AUTOSAR XML (schema 00048)
package /ComponentTypes
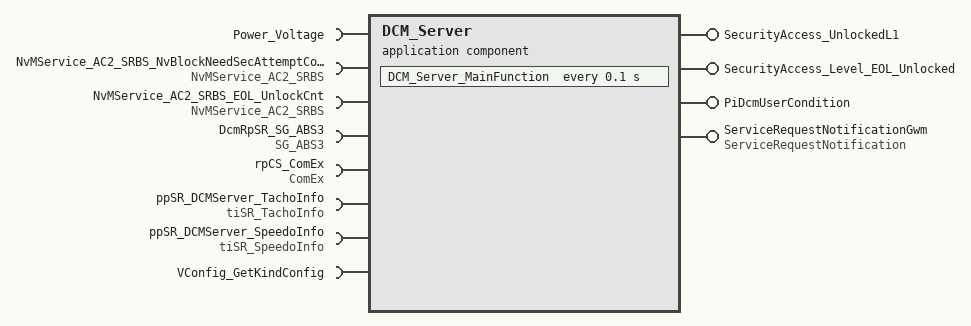
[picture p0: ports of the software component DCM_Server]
  application sw component type DCM_Server
    provide port SecurityAccess_UnlockedL1: provided-interface=SecurityAccess_UnlockedL1
      provided-com-specs:
        operation=CompareKey, queue-length=1
        operation=GetSeed, queue-length=1
        operation=SetSecurityAttemptCounter, queue-length=1
        operation=GetSecurityAttemptCounter, queue-length=1
    provide port SecurityAccess_Level_EOL_Unlocked: provided-interface=SecurityAccess_Level_EOL_Unlocked
      provided-com-specs:
        operation=CompareKey, queue-length=1
        operation=GetSeed, queue-length=1
        operation=SetSecurityAttemptCounter, queue-length=1
        operation=GetSecurityAttemptCounter, queue-length=1
    require port Power_Voltage: nonqueued-receiver-com-spec{data-element=Element, filter=data-filter-type=ALWAYS, init-value=fields=[state:0, value:0]}, required-interface=Power_Voltage
    require port NvMService_AC2_SRBS_NvBlockNeedSecAttemptCount: required-com-specs=[WriteBlock, SetRamBlockStatus, ReadBlock, GetErrorStatus], required-interface=NvMService_AC2_SRBS
    require port NvMService_AC2_SRBS_EOL_UnlockCnt: required-com-specs=[WriteBlock, SetRamBlockStatus, ReadBlock, GetErrorStatus], required-interface=NvMService_AC2_SRBS
    provide port PiDcmUserCondition: mode-switch-sender-com-spec{mode-group=Mode, queue-length=1}, provided-interface=PiDcmUserCondition
    require port DcmRpSR_SG_ABS3: nonqueued-receiver-com-spec{data-element=SG_ABS3, alive-timeout=0.2, enable-update=true, handle-never-received=true, init-value=fields=[ABSActv_0x265:0, ABSFailSts_0x265:1, CheckSum_ABS3_0x265:0, dummy_ABS3_0:0, dummy_ABS3_1:0, dummy_ABS3_2:0, dummy_ABS3_3:0, EBDActv_0x265:0, EBDFailSts_0x265:0, RollingCounter_ABS3_0x265:0, VehOdoInfo_0x265:0, VehOdoInfoSts_0x265:1, VehSpd_0x265:0, VehSpdVld_0x265:0]}, required-interface=SG_ABS3
    provide port ServiceRequestNotificationGwm: provided-com-specs=[{operation=Confirmation, queue-length=1}, {operation=Indication, queue-length=1}], provided-interface=ServiceRequestNotification
    4 x require port:
      rpCS_ComEx: required-com-specs=[SendSignal, ReceiveSignal, GetRxE2EStatus], required-interface=ComEx
      ppSR_DCMServer_TachoInfo: nonqueued-receiver-com-spec{data-element=Element, filter=data-filter-type=ALWAYS, init-value=fields=[EngRunSts:0, EngSpd:0, TimeOutFlag:0, EngSpdBak:0, Msg_missingSts:0]}, required-interface=tiSR_TachoInfo
      ppSR_DCMServer_SpeedoInfo: nonqueued-receiver-com-spec{data-element=Element, filter=data-filter-type=ALWAYS, init-value=fields=[OverSpdWrnFlg:0, VehRunSts:0, IndicateSpeed:0, RealSpeed:0, IndicateSpeedMile:0, RealSpeedMile:0, RealSpeedBak:0, Msg_missingSts:0, VehSpdVld:0]}, required-interface=tiSR_SpeedoInfo
      VConfig_GetKindConfig: client-com-spec=Operation_VConfig_GetKindConfig, required-interface=VConfig_GetKindConfig
    behavior DCM_Server_InternalBehavior: port-api-option{enable-take-address=true, error-handling=NO-TRANSFORMER-ERROR-HANDLING, indirect-api=false, port=ServiceRequestNotificationGwm}
      ar-typed-per-instance-memorys:
        5 x data, all with sw-calibration-access=READ-ONLY:
          NvBlockNeedSecAttmptCount_MirrorBlock: type=A_1Bytes
          NvBlockNeed_Dcm_ECUlevelNetworkConfigurationDataIdentifier_MirrorBlock: type=A_200Bytes
          NvBlockNeed_Dcm_VIN_MirrorBlock: type=A_17Bytes
          NvBlockNeedSecAttemptCount_MirrorBlock: type=A_1Bytes
          NvBlockNeed_EOLUnlockCnt_MirrorBlock: type=A_1Bytes
      timing event TMT_Runnable: start-on-event=DCM_Server_MainFunction, period=0.1
      4 x operation invoked event:
        OIT_SecurityAccess_Level_EOL_Unlocked_CompareKey_SecurityAccess_Level_EOL_Unlocked_CompareKey: start-on-event=SecurityAccess_Level_EOL_Unlocked_CompareKey, operation=SecurityAccess_Level_EOL_Unlocked.CompareKey
        OIT_SecurityAccess_Level_EOL_Unlocked_GetSeed_SecurityAccess_Level_EOL_Unlocked_GetSeed: start-on-event=SecurityAccess_Level_EOL_Unlocked_GetSeed, operation=SecurityAccess_Level_EOL_Unlocked.GetSeed
        OIT_SecurityAccess_UnlockedL1_CompareKey_SecurityAccess_UnlockedL1_CompareKey: start-on-event=SecurityAccess_UnlockedL1_CompareKey, operation=SecurityAccess_UnlockedL1.CompareKey
        OIT_SecurityAccess_UnlockedL1_GetSeed_SecurityAccess_UnlockedL1_GetSeed: start-on-event=SecurityAccess_UnlockedL1_GetSeed, operation=SecurityAccess_UnlockedL1.GetSeed
      init event DCM_Server_InitEvent: start-on-event=DCM_Server_Init
      6 x operation invoked event:
        OIT_SecurityAccess_UnlockedL1_SetSecurityAttemptCounter_SecurityAccess_UnlockedL1_SetSecurityAttemptCounter: start-on-event=SecurityAccess_UnlockedL1_SetSecurityAttemptCounter, operation=SecurityAccess_UnlockedL1.SetSecurityAttemptCounter
        OIT_SecurityAccess_UnlockedL1_GetSecurityAttemptCounter_SecurityAccess_UnlockedL1_GetSecurityAttemptCounter: start-on-event=SecurityAccess_UnlockedL1_GetSecurityAttemptCounter, operation=SecurityAccess_UnlockedL1.GetSecurityAttemptCounter
        OIT_SecurityAccess_Level_EOL_Unlocked_SetSecurityAttemptCounter_SecurityAccess_Level_EOL_Unlocked_SetSecurityAttemptCounter: start-on-event=SecurityAccess_Level_EOL_Unlocked_SetSecurityAttemptCounter, operation=SecurityAccess_Level_EOL_Unlocked.SetSecurityAttemptCounter
        OIT_SecurityAccess_Level_EOL_Unlocked_GetSecurityAttemptCounter_SecurityAccess_Level_EOL_Unlocked_GetSecurityAttemptCounter: start-on-event=SecurityAccess_Level_EOL_Unlocked_GetSecurityAttemptCounter, operation=SecurityAccess_Level_EOL_Unlocked.GetSecurityAttemptCounter
        OIT_ServiceRequestNotificationGwm_Confirmation_ServiceRequestNotificationGwm_Confirmation: start-on-event=ServiceRequestNotificationGwm_Confirmation, operation=ServiceRequestNotificationGwm.Confirmation
        OIT_ServiceRequestNotificationGwm_Indication_ServiceRequestNotificationGwm_Indication: start-on-event=ServiceRequestNotificationGwm_Indication, operation=ServiceRequestNotificationGwm.Indication
      12 x runnable:
        DCM_Server_MainFunction
          data-receive-point-by-arguments:
            access REC_DcmRpSR_SG_ABS3_SG_ABS3: accessed-variable=DcmRpSR_SG_ABS3.SG_ABS3
            access REC_ppSR_DCMServer_SpeedoInfo_Element: accessed-variable=ppSR_DCMServer_SpeedoInfo.Element
            access REC_ppSR_DCMServer_TachoInfo_Element: accessed-variable=ppSR_DCMServer_TachoInfo.Element
          mode switch point SWITCH_PiDcmUserCondition_Mode: mode-group=PiDcmUserCondition.Mode
          10 x sync call:
            SC_NvMService_AC2_SRBS_NvBlockNeedSecAttemptCount_ReadBlock: operation=NvMService_AC2_SRBS_NvBlockNeedSecAttemptCount.ReadBlock
            SC_NvMService_AC2_SRBS_NvBlockNeedSecAttemptCount_WriteBlock: operation=NvMService_AC2_SRBS_NvBlockNeedSecAttemptCount.WriteBlock
            SC_NvMService_AC2_SRBS_EOL_UnlockCnt_ReadBlock: operation=NvMService_AC2_SRBS_EOL_UnlockCnt.ReadBlock
            SC_NvMService_AC2_SRBS_EOL_UnlockCnt_WriteBlock: operation=NvMService_AC2_SRBS_EOL_UnlockCnt.WriteBlock
            SC_rpCS_ComEx_ReceiveSignal: operation=rpCS_ComEx.ReceiveSignal
            SC_rpCS_ComEx_GetRxE2EStatus: operation=rpCS_ComEx.GetRxE2EStatus
            SC_rpCS_ComEx_SendSignal: operation=rpCS_ComEx.SendSignal
            SC_NvMService_AC2_SRBS_EOL_UnlockCnt_GetErrorStatus: operation=NvMService_AC2_SRBS_EOL_UnlockCnt.GetErrorStatus
            SC_NvMService_AC2_SRBS_NvBlockNeedSecAttemptCount_GetErrorStatus: operation=NvMService_AC2_SRBS_NvBlockNeedSecAttemptCount.GetErrorStatus
            SC_VConfig_GetKindConfig_Operation_VConfig_GetKindConfig: operation=VConfig_GetKindConfig.Operation_VConfig_GetKindConfig
        SecurityAccess_Level_EOL_Unlocked_CompareKey
        SecurityAccess_Level_EOL_Unlocked_GetSeed
        SecurityAccess_UnlockedL1_CompareKey
        SecurityAccess_UnlockedL1_GetSeed
        DCM_Server_Init
        SecurityAccess_UnlockedL1_SetSecurityAttemptCounter
        SecurityAccess_UnlockedL1_GetSecurityAttemptCounter
        SecurityAccess_Level_EOL_Unlocked_SetSecurityAttemptCounter
        SecurityAccess_Level_EOL_Unlocked_GetSecurityAttemptCounter
        ServiceRequestNotificationGwm_Confirmation
        ServiceRequestNotificationGwm_Indication
      swc service dependency NvBlockNeedSecAttemptCount: assigned-ports=role-based-port-assignment={port-prototype=NvMService_AC2_SRBS_NvBlockNeedSecAttemptCount, role=NvMService_AC2_SRBS}
        assigned-datas:
          role=ramBlock, used-data-element=NvBlockNeedSecAttemptCount_MirrorBlock
          role=defaultValue, used-parameter-element=NvBlockNeedSecAttemptCount_DefaultValue
        service-needs:
          nv block needs NvBlockNeedSecAttemptCount: n-data-sets=0, ram-block-status-control=API, reliability=NO-PROTECTION, restore-at-start=true
      swc service dependency NvBlockNeed_EOLUnlockCnt: assigned-ports=role-based-port-assignment={port-prototype=NvMService_AC2_SRBS_EOL_UnlockCnt, role=NvMService_AC2_SRBS}
        assigned-datas:
          role=ramBlock, used-data-element=NvBlockNeed_EOLUnlockCnt_MirrorBlock
          role=defaultValue, used-parameter-element=NvBlockNeed_EOLUnlockCnt_DefaultValue
        service-needs:
          nv block needs NvBlockNeed_EOLUnlockCnt: n-data-sets=0, ram-block-status-control=API, reliability=NO-PROTECTION, restore-at-start=true
      shared-parameters:
        parameter data prototype NvBlockNeed_EOLUnlockCnt_DefaultValue: sw-calibration-access=READ-WRITE, type=A_1Bytes, init-value=[0]
        parameter data prototype NvBlockNeedSecAttemptCount_DefaultValue: sw-calibration-access=READ-WRITE, type=A_1Bytes, init-value=[0]
  swc implementation DCM_Server_Implementation: behavior=DCM_Server_InternalBehavior
